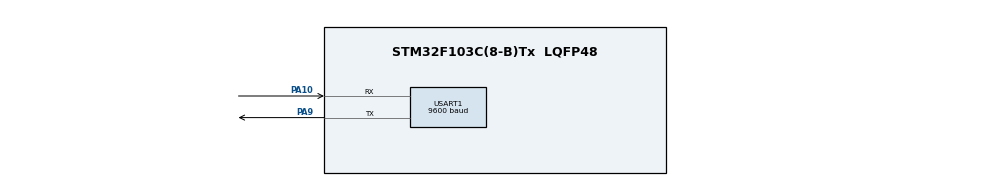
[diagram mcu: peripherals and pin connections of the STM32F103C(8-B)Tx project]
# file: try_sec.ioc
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FREERTOS.Tasks01=defaultTask,24,128,StartDefaultTask,Default,NULL,Dynamic,NULL,NULL
Mcu.Family=STM32F1
Mcu.Name=STM32F103C(8-B)Tx
Mcu.Package=LQFP48
NVIC.PriorityGroup=NVIC_PRIORITYGROUP_4
NVIC.TIM1_UP_IRQn=true\:0\:0\:false\:false\:true\:false\:false\:true
NVIC.TimeBase=TIM1_UP_IRQn
NVIC.TimeBaseIP=TIM1
PA10.Mode=Asynchronous
PA10.Signal=USART1_RX
PA13.Mode=Trace_Asynchronous_SW
PA13.Signal=SYS_JTMS-SWDIO
PA14.Mode=Trace_Asynchronous_SW
PA14.Signal=SYS_JTCK-SWCLK
PA9.Mode=Asynchronous
PA9.Signal=USART1_TX
PB3.Mode=Trace_Asynchronous_SW
PB3.Signal=SYS_JTDO-TRACESWO
ProjectManager.HeapSize=0x200
ProjectManager.StackSize=0x400
ProjectManager.TargetToolchain=STM32CubeIDE
RCC.APB1Freq_Value=8000000
RCC.APB2Freq_Value=8000000
USART1.BaudRate=9600
USART1.VirtualMode=VM_ASYNC
VP_FREERTOS_VS_CMSIS_V2.Mode=CMSIS_V2
VP_SYS_VS_tim1.Mode=TIM1
board=custom

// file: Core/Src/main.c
/* USER CODE BEGIN Header */
/**
  ******************************************************************************
  * @file           : main.c
  * @brief          : Main program body
  ******************************************************************************
  * @attention
  *
  * <h2><center>&copy; Copyright (c) 2021 STMicroelectronics.
  * All rights reserved.</center></h2>
  *
  * This software component is licensed by ST under BSD 3-Clause license,
  * the "License"; You may not use this file except in compliance with the
  * License. You may obtain a copy of the License at:
  *                        opensource.org/licenses/BSD-3-Clause
  *
  ******************************************************************************
  */
/* USER CODE END Header */
#include "main.h"
#include "cmsis_os.h"

/* USER CODE BEGIN Includes */
#include "FreeRTOS.h"
#include "task.h"
#include "queue.h"
#include "semphr.h"
#include "event_groups.h"
#include <string.h>
#include <strings.h>
/* USER CODE END Includes */

UART_HandleTypeDef huart1;

/* Definitions for defaultTask */
osThreadId_t defaultTaskHandle;
const osThreadAttr_t defaultTask_attributes = {
  .name = "defaultTask",
  .priority = (osPriority_t) osPriorityNormal,
  .stack_size = 128 * 4
};

void SystemClock_Config(void);
static void MX_GPIO_Init(void);
static void MX_USART1_UART_Init(void);
void StartDefaultTask(void *argument);

/* USER CODE BEGIN PFP */
void T_1(void);
void T_2(void);
void T_3(void);
void T_4(void);
//void system_init(void);
/* USER CODE END PFP */

/* USER CODE BEGIN 0 */
 xSemaphoreHandle Uart_handler = NULL;
 TaskStatus_t xtaskDetails;
 UBaseType_t cur_pri;
 xTaskHandle t_2;
 xTaskHandle t_3;
 /* USER CODE END 0 */

int main(void)
{

  /* MCU Configuration--------------------------------------------------------*/

  /* Reset of all peripherals, Initializes the Flash interface and the Systick. */
  HAL_Init();

  /* Configure the system clock */
  SystemClock_Config();
  Uart_handler = xSemaphoreCreateMutex();

  /* Initialize all configured peripherals */
  MX_GPIO_Init();
  MX_USART1_UART_Init();

  /* Init scheduler */
//  osKernelInitialize();

  /* Create the thread(s) */
  /* creation of defaultTask */
  //defaultTaskHandle = osThreadNew(StartDefaultTask, NULL, &defaultTask_attributes);

  /* USER CODE BEGIN RTOS_THREADS */
  /* add threads, ... */
  	 xTaskCreate(T_1,NULL,100,NULL,1,NULL);
  	 /// 	xTaskCreate(T_2,NULL,100,NULL,2,NULL);
 	 // 	xTaskCreate(T_3,NULL,100,NULL,3,NULL);
   //	xTaskCreate(T_4,NULL,100,NULL,4,NULL);
  /* USER CODE END RTOS_THREADS */

  /* Start scheduler */
 // osKernelStart();
   vTaskStartScheduler();
  /* We should never get here as control is now taken by the scheduler */
  /* Infinite loop */
  while (1)
  {

  }
}

void SystemClock_Config(void)
{
  RCC_OscInitTypeDef RCC_OscInitStruct = {0};
  RCC_ClkInitTypeDef RCC_ClkInitStruct = {0};

  /** Initializes the RCC Oscillators according to the specified parameters
  * in the RCC_OscInitTypeDef structure.
  */
  RCC_OscInitStruct.OscillatorType = RCC_OSCILLATORTYPE_HSI;
  RCC_OscInitStruct.HSIState = RCC_HSI_ON;
  RCC_OscInitStruct.HSICalibrationValue = RCC_HSICALIBRATION_DEFAULT;
  RCC_OscInitStruct.PLL.PLLState = RCC_PLL_NONE;
  if (HAL_RCC_OscConfig(&RCC_OscInitStruct) != HAL_OK)
  {
    Error_Handler();
  }
  /** Initializes the CPU, AHB and APB buses clocks
  */
  RCC_ClkInitStruct.ClockType = RCC_CLOCKTYPE_HCLK|RCC_CLOCKTYPE_SYSCLK
                              |RCC_CLOCKTYPE_PCLK1|RCC_CLOCKTYPE_PCLK2;
  RCC_ClkInitStruct.SYSCLKSource = RCC_SYSCLKSOURCE_HSI;
  RCC_ClkInitStruct.AHBCLKDivider = RCC_SYSCLK_DIV1;
  RCC_ClkInitStruct.APB1CLKDivider = RCC_HCLK_DIV1;
  RCC_ClkInitStruct.APB2CLKDivider = RCC_HCLK_DIV1;

  if (HAL_RCC_ClockConfig(&RCC_ClkInitStruct, FLASH_LATENCY_0) != HAL_OK)
  {
    Error_Handler();
  }
}

static void MX_USART1_UART_Init(void)
{

  huart1.Instance = USART1;
  huart1.Init.BaudRate = 9600;
  huart1.Init.WordLength = UART_WORDLENGTH_8B;
  huart1.Init.StopBits = UART_STOPBITS_1;
  huart1.Init.Parity = UART_PARITY_NONE;
  huart1.Init.Mode = UART_MODE_TX_RX;
  huart1.Init.HwFlowCtl = UART_HWCONTROL_NONE;
  huart1.Init.OverSampling = UART_OVERSAMPLING_16;
  if (HAL_UART_Init(&huart1) != HAL_OK)
  {
    Error_Handler();
  }

}

static void MX_GPIO_Init(void)
{

  /* GPIO Ports Clock Enable */
  __HAL_RCC_GPIOA_CLK_ENABLE();
  __HAL_RCC_GPIOB_CLK_ENABLE();

}

void T_1(void)
{

	HAL_UART_Transmit(&huart1, (uint8_t*)"T_1 Started \r\n", strlen("T_1 Started \r\n"), 10*2);//(UART_0,"T_2 Started \r\n");
     cur_pri = uxTaskPriorityGet(NULL);
	while(1)
	{
		//PRINT HERE PRIORITY
	//	xTaskHandle t_2;
	 //   xTaskHandle t_3;
	//cur_pri   = xtaskDetails.uxCurrentPriority;
			if(xSemaphoreTake(Uart_handler,portMAX_DELAY)){

		 BaseType_t returned = xTaskCreate(T_3, NULL, 100, NULL,3, &t_3);
	    //PRINT HERE PRIORITY
	   // cur_pri   = xtaskDetails.uxCurrentPriority;
		 cur_pri = uxTaskPriorityGet(NULL);
	     BaseType_t ret=  xTaskCreate(T_2, NULL, 100, NULL,2, &t_2);
	    //PRINT HERE PRIORITY
	     HAL_UART_Transmit(&huart1, (uint8_t*)"T_1\r\n", strlen("T_1 Started \r\n"), 10*2);
	     xSemaphoreGive(Uart_handler);
		//vTaskDelay(1000);
	     //PRINT HERE PRIORITY
	     cur_pri = uxTaskPriorityGet(NULL);
	     //  cur_pri   = xtaskDetails.uxCurrentPriority;
	   //  vTaskDelay(500);
	}
}
}

void T_2(void)
{
	HAL_UART_Transmit(&huart1,(uint8_t*)"T_2 Started \r\n", strlen("T_2 Started \r\n"), 10*2);//(UART_0,"T_2 Started \r\n");
	while(1)
	{
		HAL_UART_Transmit(&huart1,(uint8_t*)"T_2\r\n", strlen("T_2 Started \r\n"), 10*2);
     //	vTaskDelay(500);
	vTaskDelete(NULL);
	}
}

void T_3(void)
{
	HAL_UART_Transmit(&huart1, (uint8_t*)"T_3 Started \r\n", strlen("T_3 Started \r\n"), 10*2);//(UART_0,"T_2 Started \r\n");
		while(1)
		{
			if(xSemaphoreTake(Uart_handler,portMAX_DELAY)){

			HAL_UART_Transmit(&huart1, (uint8_t*)"T_3\r\n", strlen("T_3 Started \r\n"), 10*2);

			xSemaphoreGive(Uart_handler);
			//vTaskDelay(500);
			vTaskDelete(NULL);
		}
		}
}

void T_4(void)
{
	HAL_UART_Transmit(&huart1, (uint8_t*)"T_4 Started \r\n", strlen("T_4 Started \r\n"), 10*2);//(UART_0,"T_2 Started \r\n");
		while(1)
		{
			HAL_UART_Transmit(&huart1, (uint8_t*)"T_4\r\n", strlen("T_4 Started \r\n"), 10*2);
		vTaskDelay(1000);
		}
}

void StartDefaultTask(void *argument)
{
  for(;;)
  {
    osDelay(1);
  }
}

void HAL_TIM_PeriodElapsedCallback(TIM_HandleTypeDef *htim)
{
  if (htim->Instance == TIM1) {
    HAL_IncTick();
  }
}

void Error_Handler(void)
{
}

/************************ (C) COPYRIGHT STMicroelectronics *****END OF FILE****/
